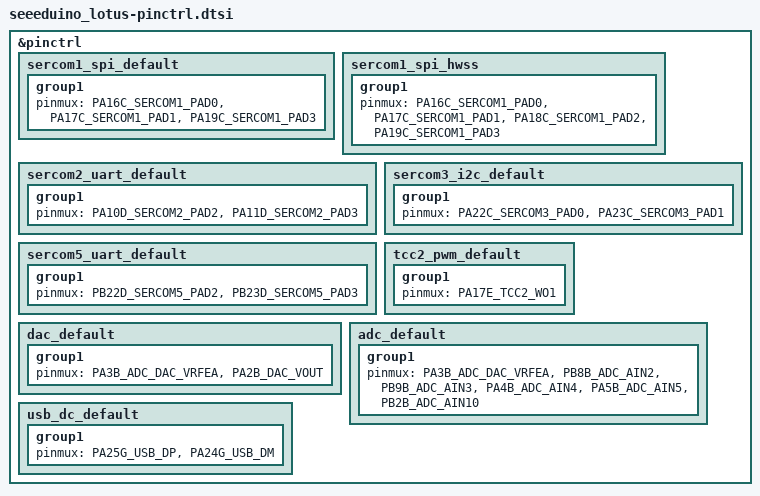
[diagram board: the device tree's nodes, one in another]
/*
 * Copyright (c) 2023 TiaC Systems
 * SPDX-License-Identifier: Apache-2.0
 */

#include <dt-bindings/pinctrl/samd21-da1gXabcd-pinctrl.h>

&pinctrl {
	sercom1_spi_default: sercom1_spi_default {
		group1 {
			pinmux = <PA16C_SERCOM1_PAD0>,
				 <PA17C_SERCOM1_PAD1>,
				 <PA19C_SERCOM1_PAD3>;
		};
	};

	sercom1_spi_hwss: sercom1_spi_hwss {
		group1 {
			pinmux = <PA16C_SERCOM1_PAD0>,
				 <PA17C_SERCOM1_PAD1>,
				 <PA18C_SERCOM1_PAD2>,
				 <PA19C_SERCOM1_PAD3>;
		};
	};

	sercom2_uart_default: sercom2_uart_default {
		group1 {
			pinmux = <PA10D_SERCOM2_PAD2>,
				 <PA11D_SERCOM2_PAD3>;
		};
	};

	sercom3_i2c_default: sercom3_i2c_default {
		group1 {
			pinmux = <PA22C_SERCOM3_PAD0>,
				 <PA23C_SERCOM3_PAD1>;
		};
	};

	sercom5_uart_default: sercom5_uart_default {
		group1 {
			pinmux = <PB22D_SERCOM5_PAD2>,
				 <PB23D_SERCOM5_PAD3>;
		};
	};

	tcc2_pwm_default: tcc2_pwm_default {
		group1 {
			pinmux = <PA17E_TCC2_WO1>;
		};
	};

	dac_default: dac_default {
		group1 {
			pinmux = <PA3B_ADC_DAC_VRFEA>,
				 <PA2B_DAC_VOUT>;
		};
	};

	adc_default: adc_default {
		group1 {
			pinmux = <PA3B_ADC_DAC_VRFEA>,
				 <PB8B_ADC_AIN2>,
				 <PB9B_ADC_AIN3>,
				 <PA4B_ADC_AIN4>,
				 <PA5B_ADC_AIN5>,
				 <PB2B_ADC_AIN10>;
		};
	};

	usb_dc_default: usb_dc_default {
		group1 {
			pinmux = <PA25G_USB_DP>,
				 <PA24G_USB_DM>;
		};
	};
};
